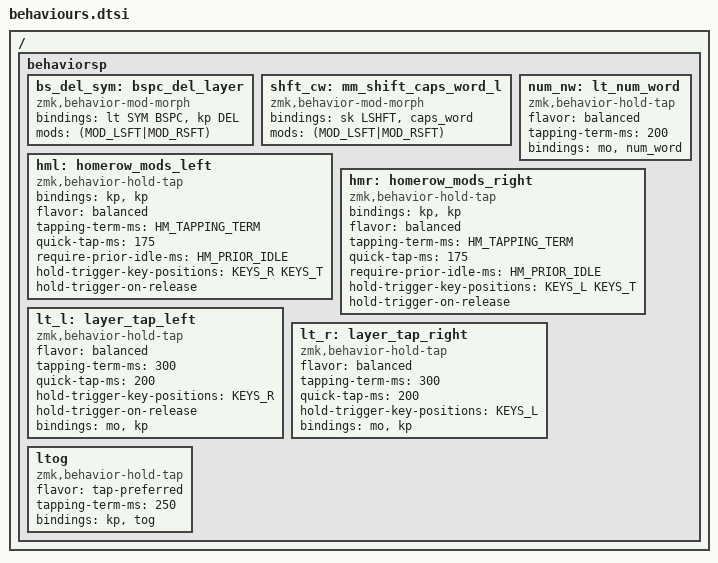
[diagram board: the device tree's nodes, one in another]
#include <dt-bindings/zmk/outputs.h>

#define HM_TAPPING_TERM 280
#define HM_TAPPING_TERM_FAST 200
#define HM_PRIOR_IDLE 150
#define TD_TAPPING_TERM 300
/ {
  behaviorsp {
        /*
         * Shifted Backspace deletes + Layer Tap
         *
         * Usage: &mm_bspc_del_layer
         * Tap: Backspace
         * Shift-Tap: Delete
         * Hold: Switch layer SYM
         */
        bs_del_sym: bspc_del_layer {
            compatible = "zmk,behavior-mod-morph";
            #binding-cells = <0>;
            bindings = <&lt SYM BSPC>, <&kp DEL>;
            mods = <(MOD_LSFT|MOD_RSFT)>;
        };

        /*
         * Sticky shift + Caps Word
         *
         * Usage: &mm_shift_caps_word_l or &mm_shift_caps_word_r
         * Tap: Sticky shift
         * HMR-Shift-Tap: Caps Word
         * Double Tap: Caps Word
         *   - The first tap activates sticky shift mod
         *   - The second tap is now a shift + press, which activates
         *     the mod morph
         * Hold: Shift
         *
         * Credits to urob for this genius combo.
         */

        shft_cw: mm_shift_caps_word_l {
            compatible = "zmk,behavior-mod-morph";
            #binding-cells = <0>;

            bindings = <&sk LSHFT>, <&caps_word>;

            mods = <(MOD_LSFT|MOD_RSFT)>;
        };

        num_nw: lt_num_word {
            compatible = "zmk,behavior-hold-tap";
            #binding-cells = <2>;
            flavor = "balanced";
            tapping-term-ms = <200>;

            bindings = <&mo>, <&num_word>;
        };

        hml: homerow_mods_left {
            compatible = "zmk,behavior-hold-tap";
            #binding-cells = <2>;
            bindings = <&kp>,  <&kp>;

            flavor = "balanced";
            tapping-term-ms = <HM_TAPPING_TERM>;
            quick-tap-ms = <175>;                // repeat on tap-into-hold
            require-prior-idle-ms = <HM_PRIOR_IDLE>;

            hold-trigger-key-positions = <KEYS_R KEYS_T>;
            hold-trigger-on-release;
        };

        hmr: homerow_mods_right {
            compatible = "zmk,behavior-hold-tap";
            #binding-cells = <2>;
            bindings = <&kp>, <&kp>;

            flavor = "balanced";
            tapping-term-ms = <HM_TAPPING_TERM>;
            quick-tap-ms = <175>;
            require-prior-idle-ms = <HM_PRIOR_IDLE>;

            hold-trigger-key-positions = <KEYS_L KEYS_T>;
            hold-trigger-on-release;
        };

       /*
        * Timerless Layer Tap
        *
        * Works similarly timerless homerow mods. It activates the
        * layer hold immediately for keys on the right side.
        */
        lt_l: layer_tap_left {
            compatible = "zmk,behavior-hold-tap";
            #binding-cells = <2>;
            flavor = "balanced";
            tapping-term-ms = <300>;
			      quick-tap-ms = <200>;

            // Activate layer function immediately if a key on the right
            // side of the keyboard is used.
            hold-trigger-key-positions = <KEYS_R>;
            hold-trigger-on-release;

            bindings = <&mo>, <&kp>;
        };

        lt_r: layer_tap_right {
            compatible = "zmk,behavior-hold-tap";
            #binding-cells = <2>;
            flavor = "balanced";
            tapping-term-ms = <300>;
			      quick-tap-ms = <200>;

            // Activate layer function immediately if a key on the right
            // side of the keyboard is used.
            hold-trigger-key-positions = <KEYS_L>;

            bindings = <&mo>, <&kp>;
        };

               /*
        * Layer Toggle
        *
        * Usage: &ltog LGUI NAV
        * Tap: Layer Toggle
        * Hold: Keypress
        */
        ltog: ltog {
            compatible = "zmk,behavior-hold-tap";
            #binding-cells = <2>;
            flavor = "tap-preferred";
            tapping-term-ms = <250>;
            bindings = <&kp>, <&tog>;
        };

  };
};
